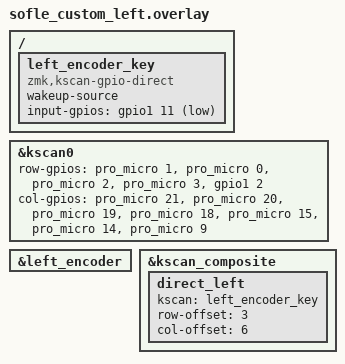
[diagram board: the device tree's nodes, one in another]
/*
 * Copyright (c) 2020 Ryan Cross
 *
 * SPDX-License-Identifier: MIT
 */

#include "sofle_custom.dtsi"
#include <dt-bindings/zmk/matrix_transform.h>

&kscan0 {
    row-gpios
        = <&pro_micro 1 (GPIO_ACTIVE_HIGH | GPIO_PULL_DOWN)>
        , <&pro_micro 0 (GPIO_ACTIVE_HIGH | GPIO_PULL_DOWN)>
        , <&pro_micro 2 (GPIO_ACTIVE_HIGH | GPIO_PULL_DOWN)>
        , <&pro_micro 3 (GPIO_ACTIVE_HIGH | GPIO_PULL_DOWN)>
        , <&gpio1 2 (GPIO_ACTIVE_HIGH | GPIO_PULL_DOWN)>
        ;

    col-gpios
        = <&pro_micro 21 GPIO_ACTIVE_HIGH>
        , <&pro_micro 20 GPIO_ACTIVE_HIGH>
        , <&pro_micro 19 GPIO_ACTIVE_HIGH>
        , <&pro_micro 18 GPIO_ACTIVE_HIGH>
        , <&pro_micro 15 GPIO_ACTIVE_HIGH>
        , <&pro_micro 14 GPIO_ACTIVE_HIGH>
        , <&pro_micro 9  GPIO_ACTIVE_HIGH>
        ;
};

&left_encoder {
    status = "okay";
};

/ {
    left_encoder_key: left_encoder_key {
        compatible = "zmk,kscan-gpio-direct";
        wakeup-source;
        input-gpios = <&gpio1 11 (GPIO_ACTIVE_LOW | GPIO_PULL_UP)>;
    };
};

&kscan_composite {
    direct_left {
        kscan = <&left_encoder_key>;
        row-offset = <3>;
        col-offset = <6>;
    };
};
